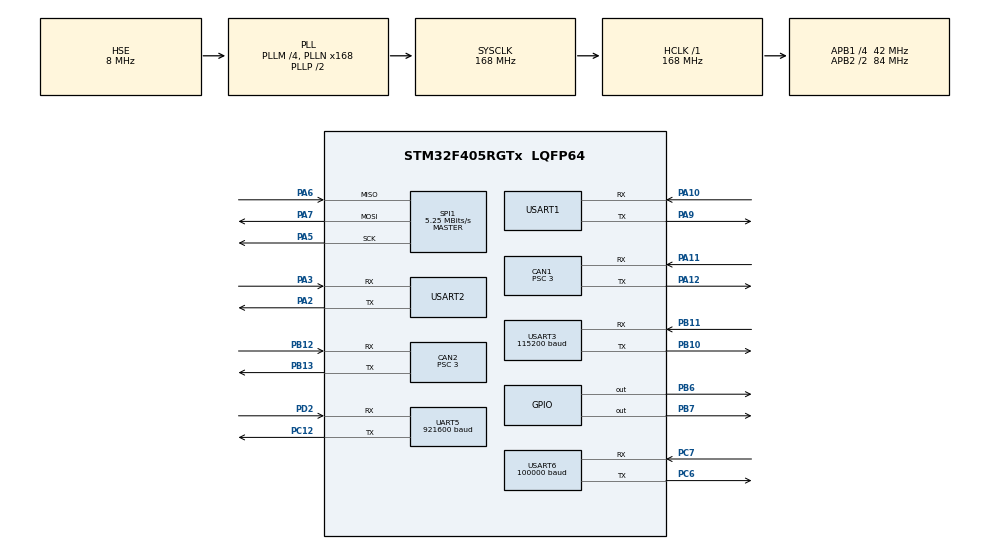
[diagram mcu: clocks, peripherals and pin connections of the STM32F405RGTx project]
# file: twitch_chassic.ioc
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CAN1.ABOM=ENABLE
CAN1.BS1=CAN_BS1_9TQ
CAN1.BS2=CAN_BS2_4TQ
CAN1.CalculateBaudRate=1000000
CAN1.CalculateTimeBit=1000
CAN1.CalculateTimeQuantum=71.42857142857143
CAN1.NART=ENABLE
CAN1.Prescaler=3
CAN2.ABOM=ENABLE
CAN2.BS1=CAN_BS1_9TQ
CAN2.BS2=CAN_BS2_4TQ
CAN2.CalculateBaudRate=1000000
CAN2.CalculateTimeBit=1000
CAN2.CalculateTimeQuantum=71.42857142857143
CAN2.NART=ENABLE
CAN2.Prescaler=3
Dma.Request0=USART3_RX
Dma.Request1=USART6_RX
Dma.Request2=USART3_TX
Dma.Request3=USART1_RX
Dma.Request4=USART1_TX
Dma.Request5=UART5_RX
Dma.Request6=UART5_TX
Dma.UART5_RX.5.Direction=DMA_PERIPH_TO_MEMORY
Dma.UART5_RX.5.FIFOMode=DMA_FIFOMODE_DISABLE
Dma.UART5_RX.5.Instance=DMA1_Stream0
Dma.UART5_RX.5.MemDataAlignment=DMA_MDATAALIGN_BYTE
Dma.UART5_RX.5.MemInc=DMA_MINC_ENABLE
Dma.UART5_RX.5.Mode=DMA_NORMAL
Dma.UART5_RX.5.PeriphDataAlignment=DMA_PDATAALIGN_BYTE
Dma.UART5_RX.5.PeriphInc=DMA_PINC_DISABLE
Dma.UART5_RX.5.Priority=DMA_PRIORITY_LOW
Dma.UART5_TX.6.Direction=DMA_MEMORY_TO_PERIPH
Dma.UART5_TX.6.FIFOMode=DMA_FIFOMODE_DISABLE
Dma.UART5_TX.6.Instance=DMA1_Stream7
Dma.UART5_TX.6.MemDataAlignment=DMA_MDATAALIGN_BYTE
Dma.UART5_TX.6.MemInc=DMA_MINC_ENABLE
Dma.UART5_TX.6.Mode=DMA_NORMAL
Dma.UART5_TX.6.PeriphDataAlignment=DMA_PDATAALIGN_BYTE
Dma.UART5_TX.6.PeriphInc=DMA_PINC_DISABLE
Dma.UART5_TX.6.Priority=DMA_PRIORITY_LOW
Dma.USART1_RX.3.Direction=DMA_PERIPH_TO_MEMORY
Dma.USART1_RX.3.FIFOMode=DMA_FIFOMODE_DISABLE
Dma.USART1_RX.3.Instance=DMA2_Stream2
Dma.USART1_RX.3.MemDataAlignment=DMA_MDATAALIGN_BYTE
Dma.USART1_RX.3.MemInc=DMA_MINC_ENABLE
Dma.USART1_RX.3.Mode=DMA_NORMAL
Dma.USART1_RX.3.PeriphDataAlignment=DMA_PDATAALIGN_BYTE
Dma.USART1_RX.3.PeriphInc=DMA_PINC_DISABLE
Dma.USART1_RX.3.Priority=DMA_PRIORITY_LOW
Dma.USART1_TX.4.Direction=DMA_MEMORY_TO_PERIPH
Dma.USART1_TX.4.FIFOMode=DMA_FIFOMODE_DISABLE
Dma.USART1_TX.4.Instance=DMA2_Stream7
Dma.USART1_TX.4.MemDataAlignment=DMA_MDATAALIGN_BYTE
Dma.USART1_TX.4.MemInc=DMA_MINC_ENABLE
Dma.USART1_TX.4.Mode=DMA_NORMAL
Dma.USART1_TX.4.PeriphDataAlignment=DMA_PDATAALIGN_BYTE
Dma.USART1_TX.4.PeriphInc=DMA_PINC_DISABLE
Dma.USART1_TX.4.Priority=DMA_PRIORITY_LOW
Dma.USART3_RX.0.Direction=DMA_PERIPH_TO_MEMORY
Dma.USART3_RX.0.FIFOMode=DMA_FIFOMODE_DISABLE
Dma.USART3_RX.0.Instance=DMA1_Stream1
Dma.USART3_RX.0.MemDataAlignment=DMA_MDATAALIGN_BYTE
Dma.USART3_RX.0.MemInc=DMA_MINC_ENABLE
Dma.USART3_RX.0.Mode=DMA_NORMAL
Dma.USART3_RX.0.PeriphDataAlignment=DMA_PDATAALIGN_BYTE
Dma.USART3_RX.0.PeriphInc=DMA_PINC_DISABLE
Dma.USART3_RX.0.Priority=DMA_PRIORITY_LOW
Dma.USART3_TX.2.Direction=DMA_MEMORY_TO_PERIPH
Dma.USART3_TX.2.FIFOMode=DMA_FIFOMODE_DISABLE
Dma.USART3_TX.2.Instance=DMA1_Stream3
Dma.USART3_TX.2.MemDataAlignment=DMA_MDATAALIGN_BYTE
Dma.USART3_TX.2.MemInc=DMA_MINC_ENABLE
Dma.USART3_TX.2.Mode=DMA_NORMAL
Dma.USART3_TX.2.PeriphDataAlignment=DMA_PDATAALIGN_BYTE
Dma.USART3_TX.2.PeriphInc=DMA_PINC_DISABLE
Dma.USART3_TX.2.Priority=DMA_PRIORITY_LOW
Dma.USART6_RX.1.Direction=DMA_PERIPH_TO_MEMORY
Dma.USART6_RX.1.FIFOMode=DMA_FIFOMODE_DISABLE
Dma.USART6_RX.1.Instance=DMA2_Stream1
Dma.USART6_RX.1.MemDataAlignment=DMA_MDATAALIGN_BYTE
Dma.USART6_RX.1.MemInc=DMA_MINC_ENABLE
Dma.USART6_RX.1.Mode=DMA_NORMAL
Dma.USART6_RX.1.PeriphDataAlignment=DMA_PDATAALIGN_BYTE
Dma.USART6_RX.1.PeriphInc=DMA_PINC_DISABLE
Dma.USART6_RX.1.Priority=DMA_PRIORITY_LOW
Mcu.Family=STM32F4
Mcu.Name=STM32F405RGTx
Mcu.Package=LQFP64
NVIC.CAN1_RX0_IRQn=true\:2\:0\:true\:false\:true\:true\:true\:true
NVIC.CAN2_RX1_IRQn=true\:2\:0\:true\:false\:true\:true\:true\:true
NVIC.DMA1_Stream0_IRQn=true\:0\:0\:false\:false\:true\:false\:true\:true
NVIC.DMA1_Stream1_IRQn=true\:0\:0\:false\:false\:true\:false\:true\:true
NVIC.DMA1_Stream3_IRQn=true\:0\:0\:false\:false\:true\:false\:true\:true
NVIC.DMA1_Stream7_IRQn=true\:0\:0\:false\:false\:true\:false\:true\:true
NVIC.DMA2_Stream1_IRQn=true\:0\:0\:false\:false\:true\:false\:true\:true
NVIC.DMA2_Stream2_IRQn=true\:0\:0\:false\:false\:true\:false\:true\:true
NVIC.DMA2_Stream7_IRQn=true\:0\:0\:false\:false\:true\:false\:true\:true
NVIC.PriorityGroup=NVIC_PRIORITYGROUP_4
NVIC.TIM2_IRQn=true\:0\:0\:true\:false\:true\:true\:true\:true
NVIC.TIM3_IRQn=true\:4\:0\:true\:false\:true\:true\:true\:true
NVIC.TIM5_IRQn=true\:4\:0\:true\:false\:true\:true\:true\:true
NVIC.TIM7_IRQn=true\:4\:0\:true\:false\:true\:true\:true\:true
NVIC.TIM8_UP_TIM13_IRQn=true\:3\:0\:true\:false\:true\:true\:true\:true
NVIC.UART5_IRQn=true\:3\:0\:true\:false\:true\:true\:true\:true
NVIC.USART1_IRQn=true\:3\:0\:true\:false\:true\:true\:true\:true
NVIC.USART3_IRQn=true\:0\:0\:true\:false\:true\:true\:true\:true
NVIC.USART6_IRQn=true\:1\:0\:true\:false\:true\:true\:true\:true
PA10.GPIO_PuPd=GPIO_PULLUP
PA10.Mode=Asynchronous
PA10.Signal=USART1_RX
PA11.Mode=CAN_Activate
PA11.Signal=CAN1_RX
PA12.Mode=CAN_Activate
PA12.Signal=CAN1_TX
PA13.Mode=Serial_Wire
PA13.Signal=SYS_JTMS-SWDIO
PA14.Mode=Serial_Wire
PA14.Signal=SYS_JTCK-SWCLK
PA2.Mode=Asynchronous
PA2.Signal=USART2_TX
PA3.Mode=Asynchronous
PA3.Signal=USART2_RX
PA5.Mode=Full_Duplex_Master
PA5.Signal=SPI1_SCK
PA6.Mode=Full_Duplex_Master
PA6.Signal=SPI1_MISO
PA7.Mode=Full_Duplex_Master
PA7.Signal=SPI1_MOSI
PA9.GPIO_PuPd=GPIO_PULLUP
PA9.Mode=Asynchronous
PA9.Signal=USART1_TX
PB10.GPIO_PuPd=GPIO_PULLUP
PB10.Mode=Asynchronous
PB10.Signal=USART3_TX
PB11.GPIO_PuPd=GPIO_PULLUP
PB11.Mode=Asynchronous
PB11.Signal=USART3_RX
PB12.Mode=CAN_Activate
PB12.Signal=CAN2_RX
PB13.Mode=CAN_Activate
PB13.Signal=CAN2_TX
PB6.Signal=GPIO_Output
PB7.Signal=GPIO_Output
PC12.Mode=Asynchronous
PC12.Signal=UART5_TX
PC6.Mode=Asynchronous
PC6.Signal=USART6_TX
PC7.Mode=Asynchronous
PC7.Signal=USART6_RX
PD2.Mode=Asynchronous
PD2.Signal=UART5_RX
PH0-OSC_IN.Mode=HSE-External-Oscillator
PH0-OSC_IN.Signal=RCC_OSC_IN
PH1-OSC_OUT.Mode=HSE-External-Oscillator
PH1-OSC_OUT.Signal=RCC_OSC_OUT
ProjectManager.HeapSize=0x3C00
ProjectManager.StackSize=0x800
ProjectManager.TargetToolchain=CMake
RCC.48MHZClocksFreq_Value=84000000
RCC.AHBFreq_Value=168000000
RCC.APB1CLKDivider=RCC_HCLK_DIV4
RCC.APB1Freq_Value=42000000
RCC.APB1TimFreq_Value=84000000
RCC.APB2CLKDivider=RCC_HCLK_DIV2
RCC.APB2Freq_Value=84000000
RCC.APB2TimFreq_Value=168000000
RCC.CortexFreq_Value=168000000
RCC.HCLKFreq_Value=168000000
RCC.HSE_VALUE=8000000
RCC.HSI_VALUE=16000000
RCC.LSE_VALUE=32768
RCC.PLLM=4
RCC.PLLN=168
RCC.PLLSourceVirtual=RCC_PLLSOURCE_HSE
RCC.SYSCLKFreq_VALUE=168000000
RCC.SYSCLKSource=RCC_SYSCLKSOURCE_PLLCLK
RCC.VCOOutputFreq_Value=336000000
SPI1.BaudRatePrescaler=SPI_BAUDRATEPRESCALER_16
SPI1.CalculateBaudRate=5.25 MBits/s
SPI1.Direction=SPI_DIRECTION_2LINES
SPI1.Mode=SPI_MODE_MASTER
SPI1.VirtualType=VM_MASTER
TIM2.Period=3333-1
TIM2.Prescaler=1680-1
TIM3.Period=1000-1
TIM3.Prescaler=168-1
TIM5.Period=1000-1
TIM5.Prescaler=840-1
TIM7.Period=1000-1
TIM7.Prescaler=84-1
TIM8.Period=1000-1
TIM8.Prescaler=84-1
UART5.BaudRate=921600
UART5.VirtualMode=Asynchronous
USART1.VirtualMode=VM_ASYNC
USART2.VirtualMode=VM_ASYNC
USART3.BaudRate=115200
USART3.VirtualMode=VM_ASYNC
USART6.BaudRate=100000
USART6.Parity=PARITY_EVEN
USART6.VirtualMode=VM_ASYNC
USART6.WordLength=WORDLENGTH_9B
VP_TIM2_VS_ClockSourceINT.Mode=Internal
VP_TIM3_VS_ClockSourceINT.Mode=Internal
VP_TIM5_VS_ClockSourceINT.Mode=Internal
VP_TIM7_VS_ClockSourceINT.Mode=Enable_Timer
VP_TIM8_VS_ClockSourceINT.Mode=Internal
board=custom

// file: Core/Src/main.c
/* USER CODE BEGIN Header */
/**
  ******************************************************************************
  * @file           : main.c
  * @brief          : Main program body
  ******************************************************************************
  * @attention
  *
  * Copyright (c) 2026 STMicroelectronics.
  * All rights reserved.
  *
  * This software is licensed under terms that can be found in the LICENSE file
  * in the root directory of this software component.
  * If no LICENSE file comes with this software, it is provided AS-IS.
  *
  ******************************************************************************
  */
/* USER CODE END Header */
#include "main.h"
#include "can.h"
#include "dma.h"
#include "spi.h"
#include "tim.h"
#include "usart.h"
#include "gpio.h"

/* USER CODE BEGIN Includes */
#include "app_chassis.h"

/* USER CODE END Includes */

void SystemClock_Config(void);

#ifndef TWITCH_CHASSIC_USE_CPP_MAIN
int main(void)
{

  /* MCU Configuration--------------------------------------------------------*/

  /* Reset of all peripherals, Initializes the Flash interface and the Systick. */
  HAL_Init();

  /* Configure the system clock */
  SystemClock_Config();

  /* Initialize all configured peripherals */
  MX_GPIO_Init();
  MX_DMA_Init();
  MX_CAN1_Init();
  MX_CAN2_Init();
  MX_SPI1_Init();
  MX_TIM3_Init();
  MX_TIM5_Init();
  MX_USART2_UART_Init();
  MX_USART3_UART_Init();
  MX_USART6_UART_Init();
  MX_TIM2_Init();
  MX_TIM7_Init();
  MX_USART1_UART_Init();
  MX_TIM8_Init();
  MX_UART5_Init();
  /* USER CODE BEGIN 2 */
  App_Chassis_Init();

  /* USER CODE END 2 */

  /* Infinite loop */
  /* USER CODE BEGIN WHILE */
  while (1)
  {
    App_Chassis_Loop();
    /* USER CODE END WHILE */

  }
}
#endif

void SystemClock_Config(void)
{
  RCC_OscInitTypeDef RCC_OscInitStruct = {0};
  RCC_ClkInitTypeDef RCC_ClkInitStruct = {0};

  /** Configure the main internal regulator output voltage
  */
  __HAL_RCC_PWR_CLK_ENABLE();
  __HAL_PWR_VOLTAGESCALING_CONFIG(PWR_REGULATOR_VOLTAGE_SCALE1);

  /** Initializes the RCC Oscillators according to the specified parameters
  * in the RCC_OscInitTypeDef structure.
  */
  RCC_OscInitStruct.OscillatorType = RCC_OSCILLATORTYPE_HSE;
  RCC_OscInitStruct.HSEState = RCC_HSE_ON;
  RCC_OscInitStruct.PLL.PLLState = RCC_PLL_ON;
  RCC_OscInitStruct.PLL.PLLSource = RCC_PLLSOURCE_HSE;
  RCC_OscInitStruct.PLL.PLLM = 4;
  RCC_OscInitStruct.PLL.PLLN = 168;
  RCC_OscInitStruct.PLL.PLLP = RCC_PLLP_DIV2;
  RCC_OscInitStruct.PLL.PLLQ = 4;
  if (HAL_RCC_OscConfig(&RCC_OscInitStruct) != HAL_OK)
  {
    Error_Handler();
  }

  /** Initializes the CPU, AHB and APB buses clocks
  */
  RCC_ClkInitStruct.ClockType = RCC_CLOCKTYPE_HCLK|RCC_CLOCKTYPE_SYSCLK
                              |RCC_CLOCKTYPE_PCLK1|RCC_CLOCKTYPE_PCLK2;
  RCC_ClkInitStruct.SYSCLKSource = RCC_SYSCLKSOURCE_PLLCLK;
  RCC_ClkInitStruct.AHBCLKDivider = RCC_SYSCLK_DIV1;
  RCC_ClkInitStruct.APB1CLKDivider = RCC_HCLK_DIV4;
  RCC_ClkInitStruct.APB2CLKDivider = RCC_HCLK_DIV2;

  if (HAL_RCC_ClockConfig(&RCC_ClkInitStruct, FLASH_LATENCY_5) != HAL_OK)
  {
    Error_Handler();
  }
}

/* USER CODE BEGIN 4 */
#ifndef TWITCH_CHASSIC_USE_CPP_MAIN
void HAL_CAN_RxFifo0MsgPendingCallback(CAN_HandleTypeDef *hcan)
{
  App_Chassis_CAN1_RxFifo0Callback(hcan);
}

void HAL_CAN_RxFifo1MsgPendingCallback(CAN_HandleTypeDef *hcan)
{
  App_Chassis_CAN2_RxFifo1Callback(hcan);
}

void HAL_TIM_PeriodElapsedCallback(TIM_HandleTypeDef *htim)
{
  App_Chassis_TIM_PeriodElapsedCallback(htim);
}

void HAL_UART_RxCpltCallback(UART_HandleTypeDef *huart)
{
  App_Chassis_UART_RxCpltCallback(huart);
}
#endif

/* USER CODE END 4 */

void Error_Handler(void)
{
  __disable_irq();
  while (1)
  {
  }
}
